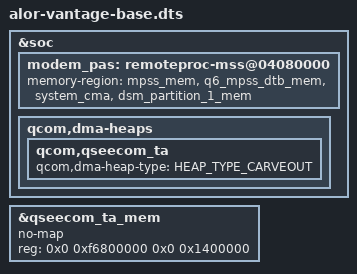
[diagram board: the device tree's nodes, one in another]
/* Copyright (c) 2025, The Linux Foundation. All rights reserved.
 *
 * This program is free software; you can redistribute it and/or modify
 * it under the terms of the GNU General Public License version 2 and
 * only version 2 as published by the Free Software Foundation.
 *
 * This program is distributed in the hope that it will be useful,
 * but WITHOUT ANY WARRANTY; without even the implied warranty of
 * MERCHANTABILITY or FITNESS FOR A PARTICULAR PURPOSE.  See the
 * GNU General Public License for more details.
 */

/dts-v1/;

#include "alor-moto-common-base.dtsi"

/delete-node/ &dsm_partition_2_mem;

&soc {
	modem_pas: remoteproc-mss@04080000 {
		memory-region = <&mpss_mem &q6_mpss_dtb_mem &system_cma &dsm_partition_1_mem>;
	};
	qcom,dma-heaps {
		qcom,qseecom_ta {
			qcom,dma-heap-type = <HEAP_TYPE_CARVEOUT>;
		};
	};
};

&qseecom_ta_mem {
	/delete-property/ reusable;
	no-map;
	reg = <0x0 0xf6800000 0x0 0x1400000>;
};
